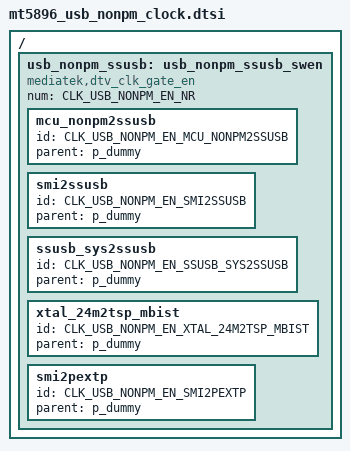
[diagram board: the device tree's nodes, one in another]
// SPDX-License-Identifier: (GPL-2.0 OR BSD-3-Clause)
/*
 * Copyright (c) 2020 MediaTek Inc.
 */


/ {
	usb_nonpm_ssusb: usb_nonpm_ssusb_swen {
		#clock-cells = <1>;
		compatible = "mediatek,dtv_clk_gate_en";
		num = <CLK_USB_NONPM_EN_NR>;

		mcu_nonpm2ssusb {
			id = <CLK_USB_NONPM_EN_MCU_NONPM2SSUSB>;
			parent = "p_dummy";
		};

		smi2ssusb {
			id = <CLK_USB_NONPM_EN_SMI2SSUSB>;
			parent = "p_dummy";
		};

		ssusb_sys2ssusb {
			id = <CLK_USB_NONPM_EN_SSUSB_SYS2SSUSB>;
			parent = "p_dummy";
		};

		xtal_24m2tsp_mbist {
			id = <CLK_USB_NONPM_EN_XTAL_24M2TSP_MBIST>;
			parent = "p_dummy";
		};

		/* PCIe clock */
		smi2pextp {
			id = <CLK_USB_NONPM_EN_SMI2PEXTP>;
			parent = "p_dummy";
		};
	};
};
